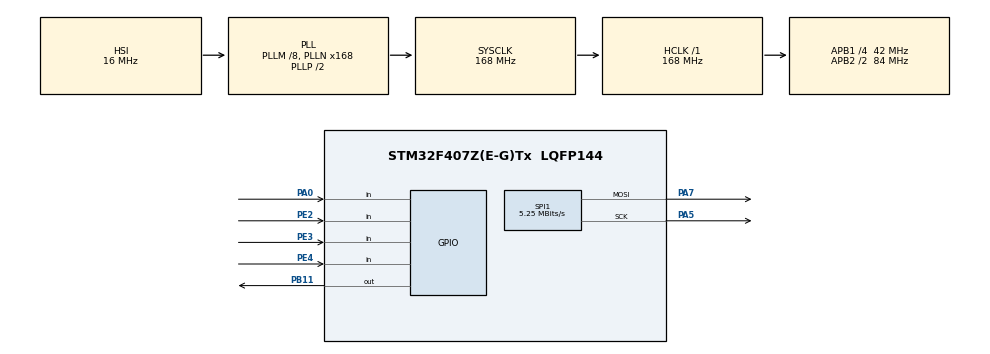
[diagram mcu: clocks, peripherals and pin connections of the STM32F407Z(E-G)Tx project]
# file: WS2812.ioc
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Dma.Request0=SPI1_TX
Dma.SPI1_TX.0.Direction=DMA_MEMORY_TO_PERIPH
Dma.SPI1_TX.0.FIFOMode=DMA_FIFOMODE_DISABLE
Dma.SPI1_TX.0.Instance=DMA2_Stream3
Dma.SPI1_TX.0.MemDataAlignment=DMA_MDATAALIGN_BYTE
Dma.SPI1_TX.0.MemInc=DMA_MINC_ENABLE
Dma.SPI1_TX.0.Mode=DMA_NORMAL
Dma.SPI1_TX.0.PeriphDataAlignment=DMA_PDATAALIGN_BYTE
Dma.SPI1_TX.0.PeriphInc=DMA_PINC_DISABLE
Dma.SPI1_TX.0.Priority=DMA_PRIORITY_LOW
Mcu.Family=STM32F4
Mcu.Name=STM32F407Z(E-G)Tx
Mcu.Package=LQFP144
NVIC.DMA2_Stream3_IRQn=true\:0\:0\:false\:false\:true\:false\:true\:true
NVIC.PriorityGroup=NVIC_PRIORITYGROUP_4
NVIC.TIM3_IRQn=true\:0\:0\:false\:false\:true\:true\:true\:true
PA0-WKUP.GPIO_PuPd=GPIO_PULLDOWN
PA0-WKUP.Signal=GPIO_Input
PA5.Mode=TX_Only_Simplex_Unidirect_Master
PA5.Signal=SPI1_SCK
PA7.Mode=TX_Only_Simplex_Unidirect_Master
PA7.Signal=SPI1_MOSI
PB11.GPIO_Speed=GPIO_SPEED_FREQ_MEDIUM
PB11.PinState=GPIO_PIN_SET
PB11.Signal=GPIO_Output
PC14-OSC32_IN.Mode=LSE-External-Oscillator
PC14-OSC32_IN.Signal=RCC_OSC32_IN
PC15-OSC32_OUT.Mode=LSE-External-Oscillator
PC15-OSC32_OUT.Signal=RCC_OSC32_OUT
PE2.GPIO_PuPd=GPIO_PULLUP
PE2.Signal=GPIO_Input
PE3.GPIO_PuPd=GPIO_PULLUP
PE3.Signal=GPIO_Input
PE4.GPIO_PuPd=GPIO_PULLUP
PE4.Signal=GPIO_Input
PH0-OSC_IN.Mode=HSE-External-Oscillator
PH0-OSC_IN.Signal=RCC_OSC_IN
PH1-OSC_OUT.Mode=HSE-External-Oscillator
PH1-OSC_OUT.Signal=RCC_OSC_OUT
ProjectManager.HeapSize=0x200
ProjectManager.StackSize=0x400
ProjectManager.TargetToolchain=MDK-ARM V5.32
RCC.48MHZClocksFreq_Value=84000000
RCC.AHBFreq_Value=168000000
RCC.APB1CLKDivider=RCC_HCLK_DIV4
RCC.APB1Freq_Value=42000000
RCC.APB1TimFreq_Value=84000000
RCC.APB2CLKDivider=RCC_HCLK_DIV2
RCC.APB2Freq_Value=84000000
RCC.APB2TimFreq_Value=168000000
RCC.CortexFreq_Value=168000000
RCC.HCLKFreq_Value=168000000
RCC.HSE_VALUE=8000000
RCC.HSI_VALUE=16000000
RCC.PLLM=8
RCC.PLLN=168
RCC.RCC_RTC_Clock_Source=RCC_RTCCLKSOURCE_LSE
RCC.RCC_RTC_Clock_SourceVirtual=RCC_RTCCLKSOURCE_LSE
RCC.SYSCLKFreq_VALUE=168000000
RCC.SYSCLKSource=RCC_SYSCLKSOURCE_PLLCLK
RCC.VCOOutputFreq_Value=336000000
RTC.Date=26
RTC.Format=RTC_FORMAT_BIN
RTC.Hours=21
RTC.Minutes=32
RTC.Month=RTC_MONTH_JUNE
RTC.WeekDay=RTC_WEEKDAY_WEDNESDAY
RTC.Year=24
SPI1.BaudRatePrescaler=SPI_BAUDRATEPRESCALER_16
SPI1.CLKPhase=SPI_PHASE_2EDGE
SPI1.CLKPolarity=SPI_POLARITY_LOW
SPI1.CalculateBaudRate=5.25 MBits/s
SPI1.DataSize=SPI_DATASIZE_8BIT
SPI1.Direction=SPI_DIRECTION_2LINES
SPI1.Mode=SPI_MODE_MASTER
SPI1.VirtualType=VM_MASTER
TIM2.AutoReloadPreload=TIM_AUTORELOAD_PRELOAD_ENABLE
TIM2.Period=83
TIM2.Prescaler=0
TIM3.AutoReloadPreload=TIM_AUTORELOAD_PRELOAD_ENABLE
TIM3.Period=999
TIM3.Prescaler=83
VP_RTC_VS_RTC_Activate.Mode=RTC_Enabled
VP_RTC_VS_RTC_Calendar.Mode=RTC_Calendar
VP_TIM2_VS_ClockSourceINT.Mode=Internal
VP_TIM3_VS_ClockSourceINT.Mode=Internal
board=custom

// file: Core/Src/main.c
/* USER CODE BEGIN Header */
/**
  ******************************************************************************
  * @file           : main.c
  * @brief          : Main program body
  ******************************************************************************
  * @attention
  *
  * Copyright (c) 2024 STMicroelectronics.
  * All rights reserved.
  *
  * This software is licensed under terms that can be found in the LICENSE file
  * in the root directory of this software component.
  * If no LICENSE file comes with this software, it is provided AS-IS.
  *
  ******************************************************************************
  */
/* USER CODE END Header */
#include "main.h"
#include "dma.h"
#include "rtc.h"
#include "spi.h"
#include "tim.h"
#include "gpio.h"

/* USER CODE BEGIN Includes */
#include "Task_create.h"
/* USER CODE END Includes */

void SystemClock_Config(void);

int main(void)
{

  /* MCU Configuration--------------------------------------------------------*/

  /* Reset of all peripherals, Initializes the Flash interface and the Systick. */
  HAL_Init();

  /* Configure the system clock */
  SystemClock_Config();

  /* Initialize all configured peripherals */
  MX_GPIO_Init();
  MX_DMA_Init();
  MX_SPI1_Init();
  MX_TIM3_Init();
  MX_RTC_Init();
  MX_TIM2_Init();
  /* USER CODE BEGIN 2 */
	HAL_TIM_Base_Start_IT(&htim3);
  Task_Star();
  /* USER CODE END 2 */

  /* Infinite loop */
  while (1)
  {

  }
}

void SystemClock_Config(void)
{
  RCC_OscInitTypeDef RCC_OscInitStruct = {0};
  RCC_ClkInitTypeDef RCC_ClkInitStruct = {0};

  /** Configure the main internal regulator output voltage
  */
  __HAL_RCC_PWR_CLK_ENABLE();
  __HAL_PWR_VOLTAGESCALING_CONFIG(PWR_REGULATOR_VOLTAGE_SCALE1);

  /** Initializes the RCC Oscillators according to the specified parameters
  * in the RCC_OscInitTypeDef structure.
  */
  RCC_OscInitStruct.OscillatorType = RCC_OSCILLATORTYPE_HSI|RCC_OSCILLATORTYPE_LSE;
  RCC_OscInitStruct.LSEState = RCC_LSE_ON;
  RCC_OscInitStruct.HSIState = RCC_HSI_ON;
  RCC_OscInitStruct.HSICalibrationValue = RCC_HSICALIBRATION_DEFAULT;
  RCC_OscInitStruct.PLL.PLLState = RCC_PLL_ON;
  RCC_OscInitStruct.PLL.PLLSource = RCC_PLLSOURCE_HSI;
  RCC_OscInitStruct.PLL.PLLM = 8;
  RCC_OscInitStruct.PLL.PLLN = 168;
  RCC_OscInitStruct.PLL.PLLP = RCC_PLLP_DIV2;
  RCC_OscInitStruct.PLL.PLLQ = 4;
  if (HAL_RCC_OscConfig(&RCC_OscInitStruct) != HAL_OK)
  {
    Error_Handler();
  }

  /** Initializes the CPU, AHB and APB buses clocks
  */
  RCC_ClkInitStruct.ClockType = RCC_CLOCKTYPE_HCLK|RCC_CLOCKTYPE_SYSCLK
                              |RCC_CLOCKTYPE_PCLK1|RCC_CLOCKTYPE_PCLK2;
  RCC_ClkInitStruct.SYSCLKSource = RCC_SYSCLKSOURCE_PLLCLK;
  RCC_ClkInitStruct.AHBCLKDivider = RCC_SYSCLK_DIV1;
  RCC_ClkInitStruct.APB1CLKDivider = RCC_HCLK_DIV4;
  RCC_ClkInitStruct.APB2CLKDivider = RCC_HCLK_DIV2;

  if (HAL_RCC_ClockConfig(&RCC_ClkInitStruct, FLASH_LATENCY_5) != HAL_OK)
  {
    Error_Handler();
  }
}

void Error_Handler(void)
{
  __disable_irq();
  while (1)
  {
  }
}
